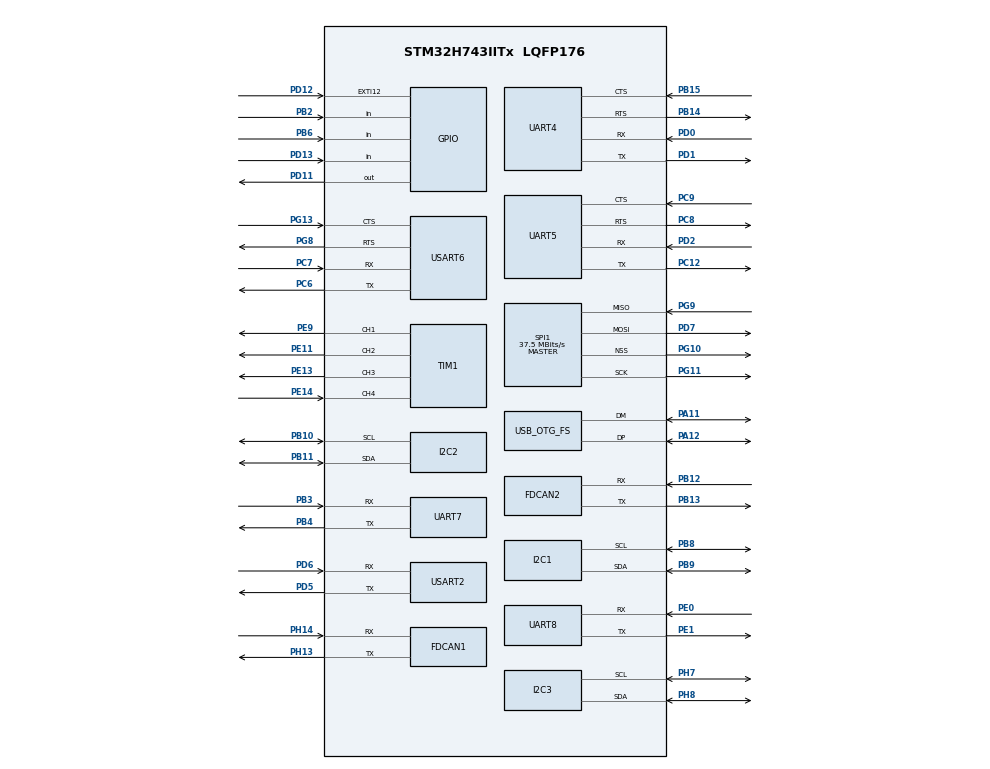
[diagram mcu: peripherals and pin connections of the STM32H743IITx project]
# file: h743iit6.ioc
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FDCAN1.CalculateBaudRateNominal=937499
FDCAN1.CalculateTimeBitNominal=1066
FDCAN1.CalculateTimeQuantumNominal=213.33333333333334
FDCAN2.CalculateBaudRateNominal=937499
FDCAN2.CalculateTimeBitNominal=1066
FDCAN2.CalculateTimeQuantumNominal=213.33333333333334
FREERTOS.Tasks01=defaultTask,24,128,StartDefaultTask,Default,NULL,Dynamic,NULL,NULL
I2C1.Timing=0x107075B0
I2C2.Timing=0x107075B0
I2C3.Timing=0x107075B0
Mcu.Family=STM32H7
Mcu.Name=STM32H743IITx
Mcu.Package=LQFP176
NVIC.PriorityGroup=NVIC_PRIORITYGROUP_4
NVIC.TIM2_IRQn=true\:15\:0\:false\:false\:true\:false\:false\:true\:true
NVIC.TimeBase=TIM2_IRQn
NVIC.TimeBaseIP=TIM2
NVIC.UART4_IRQn=true\:5\:0\:false\:false\:true\:true\:true\:true\:true
NVIC.UART5_IRQn=true\:5\:0\:false\:false\:true\:true\:true\:true\:true
PA11.Mode=Device_Only
PA11.Signal=USB_OTG_FS_DM
PA12.Mode=Device_Only
PA12.Signal=USB_OTG_FS_DP
PA14\ (JTCK/SWCLK).Signal=DEBUG_JTCK-SWCLK
PA6.Signal=S_TIM3_CH1
PA7.Signal=S_TIM3_CH2
PB0.Signal=S_TIM3_CH3
PB1.Signal=S_TIM3_CH4
PB10.Mode=I2C
PB10.Signal=I2C2_SCL
PB11.Mode=I2C
PB11.Signal=I2C2_SDA
PB12.Mode=FDCAN_Activate
PB12.Signal=FDCAN2_RX
PB13.Mode=FDCAN_Activate
PB13.Signal=FDCAN2_TX
PB14.Mode=CTS_RTS
PB14.Signal=UART4_RTS
PB15.Mode=CTS_RTS
PB15.Signal=UART4_CTS
PB2.Signal=GPIO_Input
PB3\ (JTDO/TRACESWO).Mode=Asynchronous
PB3\ (JTDO/TRACESWO).PinAttribute=Free
PB3\ (JTDO/TRACESWO).Signal=UART7_RX
PB4\ (NJTRST).Mode=Asynchronous
PB4\ (NJTRST).PinAttribute=Free
PB4\ (NJTRST).Signal=UART7_TX
PB6.PinAttribute=Free
PB6.Signal=GPIO_Input
PB8.Mode=I2C
PB8.PinAttribute=Free
PB8.Signal=I2C1_SCL
PB9.Mode=I2C
PB9.PinAttribute=Free
PB9.Signal=I2C1_SDA
PC12.Mode=Asynchronous
PC12.Signal=UART5_TX
PC6.Mode=Asynchronous
PC6.Signal=USART6_TX
PC7.Mode=Asynchronous
PC7.Signal=USART6_RX
PC8.Mode=CTS_RTS
PC8.Signal=UART5_RTS
PC9.Mode=CTS_RTS
PC9.Signal=UART5_CTS
PD0.Mode=Asynchronous
PD0.Signal=UART4_RX
PD1.Mode=Asynchronous
PD1.Signal=UART4_TX
PD11.Signal=GPIO_Output
PD12.Signal=GPXTI12
PD13.Signal=GPIO_Input
PD2.Mode=Asynchronous
PD2.Signal=UART5_RX
PD5.Mode=Asynchronous
PD5.Signal=USART2_TX
PD6.Mode=Asynchronous
PD6.Signal=USART2_RX
PD7.Mode=Full_Duplex_Master
PD7.PinAttribute=Free
PD7.Signal=SPI1_MOSI
PE0.Mode=Asynchronous
PE0.PinAttribute=Free
PE0.Signal=UART8_RX
PE1.Mode=Asynchronous
PE1.PinAttribute=Free
PE1.Signal=UART8_TX
PE11.Signal=S_TIM1_CH2
PE13.Signal=S_TIM1_CH3
PE14.Signal=S_TIM1_CH4
PE9.Signal=S_TIM1_CH1
PG10.Mode=NSS_Signal_Hard_Output
PG10.PinAttribute=Free
PG10.Signal=SPI1_NSS
PG11.Mode=Full_Duplex_Master
PG11.PinAttribute=Free
PG11.Signal=SPI1_SCK
PG13.Mode=CTS_RTS
PG13.PinAttribute=Free
PG13.Signal=USART6_CTS
PG8.Mode=CTS_RTS
PG8.Signal=USART6_RTS
PG9.Mode=Full_Duplex_Master
PG9.PinAttribute=Free
PG9.Signal=SPI1_MISO
PH0-OSC_IN\ (PH0).Mode=HSE-External-Oscillator
PH0-OSC_IN\ (PH0).Signal=RCC_OSC_IN
PH1-OSC_OUT\ (PH1).Mode=HSE-External-Oscillator
PH1-OSC_OUT\ (PH1).Signal=RCC_OSC_OUT
PH13.Mode=FDCAN_Activate
PH13.Signal=FDCAN1_TX
PH14.Mode=FDCAN_Activate
PH14.Signal=FDCAN1_RX
PH7.Mode=I2C
PH7.Signal=I2C3_SCL
PH8.Mode=I2C
PH8.Signal=I2C3_SDA
ProjectManager.HeapSize=0x200
ProjectManager.StackSize=0x400
ProjectManager.TargetToolchain=MDK-ARM V5.32
RCC.ADCFreq_Value=75000000
RCC.APB1Freq_Value=60000000
RCC.APB2Freq_Value=60000000
RCC.APB3Freq_Value=60000000
RCC.APB4Freq_Value=60000000
RCC.CortexFreq_Value=240000000
RCC.D1CPRE=RCC_SYSCLK_DIV2
RCC.D1PPRE=RCC_APB3_DIV2
RCC.D2PPRE1=RCC_APB1_DIV2
RCC.D2PPRE2=RCC_APB2_DIV2
RCC.D3PPRE=RCC_APB4_DIV2
RCC.DIVM1=5
RCC.DIVM2=25
RCC.DIVM3=15
RCC.DIVN1=192
RCC.DIVN2=150
RCC.DIVN3=180
RCC.DIVQ3=5
RCC.FDCANCLockSelection=RCC_FDCANCLKSOURCE_PLL2
RCC.HCLKFreq_Value=120000000
RCC.HPRE=RCC_HCLK_DIV2
RCC.HSE_VALUE=25000000
RCC.PLL2FRACN=0
RCC.PLL2_VCO_SEL-AdvancedSettings=RCC_PLL2VCOMEDIUM
RCC.PLL3FRACN=0
RCC.PLLFRACN=0
RCC.PLLSourceVirtual=RCC_PLLSOURCE_HSE
RCC.SPI123CLockSelection=RCC_SPI123CLKSOURCE_PLL2
RCC.SYSCLKFreq_VALUE=480000000
RCC.SYSCLKSource=RCC_SYSCLKSOURCE_PLLCLK
RCC.USBCLockSelection=RCC_USBCLKSOURCE_PLL3
RCC.USBFreq_Value=60000000
SH.S_TIM1_CH1.0=TIM1_CH1,Output Compare1 CH1
SH.S_TIM1_CH2.0=TIM1_CH2,Output Compare2 CH2
SH.S_TIM1_CH3.0=TIM1_CH3,Output Compare3 CH3
SH.S_TIM1_CH4.0=TIM1_CH4,Input_Capture4_from_TI4
SH.S_TIM3_CH1.0=TIM3_CH1
SH.S_TIM3_CH2.0=TIM3_CH2
SH.S_TIM3_CH3.0=TIM3_CH3
SH.S_TIM3_CH4.0=TIM3_CH4
SPI1.CalculateBaudRate=37.5 MBits/s
SPI1.Direction=SPI_DIRECTION_2LINES
SPI1.Mode=SPI_MODE_MASTER
SPI1.VirtualNSS=VM_NSSHARD
SPI1.VirtualType=VM_MASTER
TIM1.Channel-Input_Capture4_from_TI4=TIM_CHANNEL_4
TIM1.Channel-Output\ Compare1\ CH1=TIM_CHANNEL_1
TIM1.Channel-Output\ Compare2\ CH2=TIM_CHANNEL_2
TIM1.Channel-Output\ Compare3\ CH3=TIM_CHANNEL_3
USART2.VirtualMode-Asynchronous=VM_ASYNC
USART6.VirtualMode-Asynchronous=VM_ASYNC
USB_OTG_FS.VirtualMode=Device_Only
VP_FREERTOS_VS_CMSIS_V2.Mode=CMSIS_V2
VP_SYS_VS_tim2.Mode=TIM2
VP_TIM1_VS_ClockSourceITR.Mode=TriggerSource_ITR1
VP_TIM1_VS_ControllerModeClock.Mode=Clock Mode
board=custom

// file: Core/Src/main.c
/* USER CODE BEGIN Header */
/**
  ******************************************************************************
  * @file           : main.c
  * @brief          : Main program body
  ******************************************************************************
  * @attention
  *
  * Copyright (c) 2024 STMicroelectronics.
  * All rights reserved.
  *
  * This software is licensed under terms that can be found in the LICENSE file
  * in the root directory of this software component.
  * If no LICENSE file comes with this software, it is provided AS-IS.
  *
  ******************************************************************************
  */
/* USER CODE END Header */
#include "main.h"
#include "cmsis_os.h"
#include "fdcan.h"
#include "i2c.h"
#include "spi.h"
#include "tim.h"
#include "usart.h"
#include "usb_otg.h"
#include "gpio.h"

/* USER CODE BEGIN Includes */
#include "Task_Process.h"
#include "Callback_Function.h"
/* USER CODE END Includes */

void SystemClock_Config(void);
void PeriphCommonClock_Config(void);
void MX_FREERTOS_Init(void);

int main(void)
{

  /* MCU Configuration--------------------------------------------------------*/

  /* Reset of all peripherals, Initializes the Flash interface and the Systick. */
  HAL_Init();

  /* Configure the system clock */
  SystemClock_Config();

/* Configure the peripherals common clocks */
  PeriphCommonClock_Config();

  /* Initialize all configured peripherals */
  MX_GPIO_Init();
  MX_FDCAN1_Init();
  MX_FDCAN2_Init();
  MX_I2C1_Init();
  MX_I2C2_Init();
  MX_I2C3_Init();
  MX_SPI1_Init();
  MX_TIM1_Init();
  MX_UART4_Init();
  MX_UART5_Init();
  MX_UART7_Init();
  MX_UART8_Init();
  MX_USART2_UART_Init();
  MX_USB_OTG_FS_PCD_Init();
  MX_USART6_UART_Init();
  /* USER CODE BEGIN 2 */
	USART_IT_Init();
  /* USER CODE END 2 */

  /* Init scheduler */
  osKernelInitialize();  /* Call init function for freertos objects (in freertos.c) */
  My_Task_Creator();

  /* Start scheduler */
  osKernelStart();

  /* We should never get here as control is now taken by the scheduler */
  /* Infinite loop */
  while (1)
  {

  }
}

void SystemClock_Config(void)
{
  RCC_OscInitTypeDef RCC_OscInitStruct = {0};
  RCC_ClkInitTypeDef RCC_ClkInitStruct = {0};

  /** Supply configuration update enable
  */
  HAL_PWREx_ConfigSupply(PWR_LDO_SUPPLY);

  /** Configure the main internal regulator output voltage
  */
  __HAL_PWR_VOLTAGESCALING_CONFIG(PWR_REGULATOR_VOLTAGE_SCALE2);

  while(!__HAL_PWR_GET_FLAG(PWR_FLAG_VOSRDY)) {}

  /** Initializes the RCC Oscillators according to the specified parameters
  * in the RCC_OscInitTypeDef structure.
  */
  RCC_OscInitStruct.OscillatorType = RCC_OSCILLATORTYPE_HSE;
  RCC_OscInitStruct.HSEState = RCC_HSE_ON;
  RCC_OscInitStruct.PLL.PLLState = RCC_PLL_ON;
  RCC_OscInitStruct.PLL.PLLSource = RCC_PLLSOURCE_HSE;
  RCC_OscInitStruct.PLL.PLLM = 5;
  RCC_OscInitStruct.PLL.PLLN = 192;
  RCC_OscInitStruct.PLL.PLLP = 2;
  RCC_OscInitStruct.PLL.PLLQ = 2;
  RCC_OscInitStruct.PLL.PLLR = 2;
  RCC_OscInitStruct.PLL.PLLRGE = RCC_PLL1VCIRANGE_2;
  RCC_OscInitStruct.PLL.PLLVCOSEL = RCC_PLL1VCOWIDE;
  RCC_OscInitStruct.PLL.PLLFRACN = 0;
  if (HAL_RCC_OscConfig(&RCC_OscInitStruct) != HAL_OK)
  {
    Error_Handler();
  }

  /** Initializes the CPU, AHB and APB buses clocks
  */
  RCC_ClkInitStruct.ClockType = RCC_CLOCKTYPE_HCLK|RCC_CLOCKTYPE_SYSCLK
                              |RCC_CLOCKTYPE_PCLK1|RCC_CLOCKTYPE_PCLK2
                              |RCC_CLOCKTYPE_D3PCLK1|RCC_CLOCKTYPE_D1PCLK1;
  RCC_ClkInitStruct.SYSCLKSource = RCC_SYSCLKSOURCE_PLLCLK;
  RCC_ClkInitStruct.SYSCLKDivider = RCC_SYSCLK_DIV2;
  RCC_ClkInitStruct.AHBCLKDivider = RCC_HCLK_DIV2;
  RCC_ClkInitStruct.APB3CLKDivider = RCC_APB3_DIV2;
  RCC_ClkInitStruct.APB1CLKDivider = RCC_APB1_DIV2;
  RCC_ClkInitStruct.APB2CLKDivider = RCC_APB2_DIV2;
  RCC_ClkInitStruct.APB4CLKDivider = RCC_APB4_DIV2;

  if (HAL_RCC_ClockConfig(&RCC_ClkInitStruct, FLASH_LATENCY_2) != HAL_OK)
  {
    Error_Handler();
  }
}

void PeriphCommonClock_Config(void)
{
  RCC_PeriphCLKInitTypeDef PeriphClkInitStruct = {0};

  /** Initializes the peripherals clock
  */
  PeriphClkInitStruct.PeriphClockSelection = RCC_PERIPHCLK_SPI1|RCC_PERIPHCLK_FDCAN;
  PeriphClkInitStruct.PLL2.PLL2M = 25;
  PeriphClkInitStruct.PLL2.PLL2N = 150;
  PeriphClkInitStruct.PLL2.PLL2P = 2;
  PeriphClkInitStruct.PLL2.PLL2Q = 2;
  PeriphClkInitStruct.PLL2.PLL2R = 2;
  PeriphClkInitStruct.PLL2.PLL2RGE = RCC_PLL2VCIRANGE_0;
  PeriphClkInitStruct.PLL2.PLL2VCOSEL = RCC_PLL2VCOMEDIUM;
  PeriphClkInitStruct.PLL2.PLL2FRACN = 0;
  PeriphClkInitStruct.Spi123ClockSelection = RCC_SPI123CLKSOURCE_PLL2;
  PeriphClkInitStruct.FdcanClockSelection = RCC_FDCANCLKSOURCE_PLL2;
  if (HAL_RCCEx_PeriphCLKConfig(&PeriphClkInitStruct) != HAL_OK)
  {
    Error_Handler();
  }
}

void HAL_TIM_PeriodElapsedCallback(TIM_HandleTypeDef *htim)
{
  if (htim->Instance == TIM2) {
    HAL_IncTick();
  }
}

void Error_Handler(void)
{
  __disable_irq();
  while (1)
  {
  }
}
